AUTOSAR XML (schema 00048)
package /ara/demo/applications
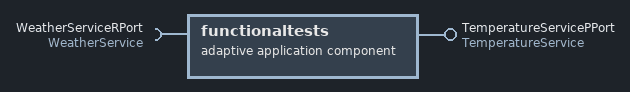
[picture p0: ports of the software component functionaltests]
  adaptive application sw component type functionaltests
    require port WeatherServiceRPort: required-interface=WeatherService
    provide port TemperatureServicePPort: provided-interface=TemperatureService
package /ara/demo/executables
  executable functionaltests_exe: category=APPLICATION_LEVEL, build-type=BUILD-TYPE-DEBUG, logging-behavior=USES-LOGGING, minimum-timer-granularity=1000.0
    root sw component prototype root_swc: application-type=functionaltests
